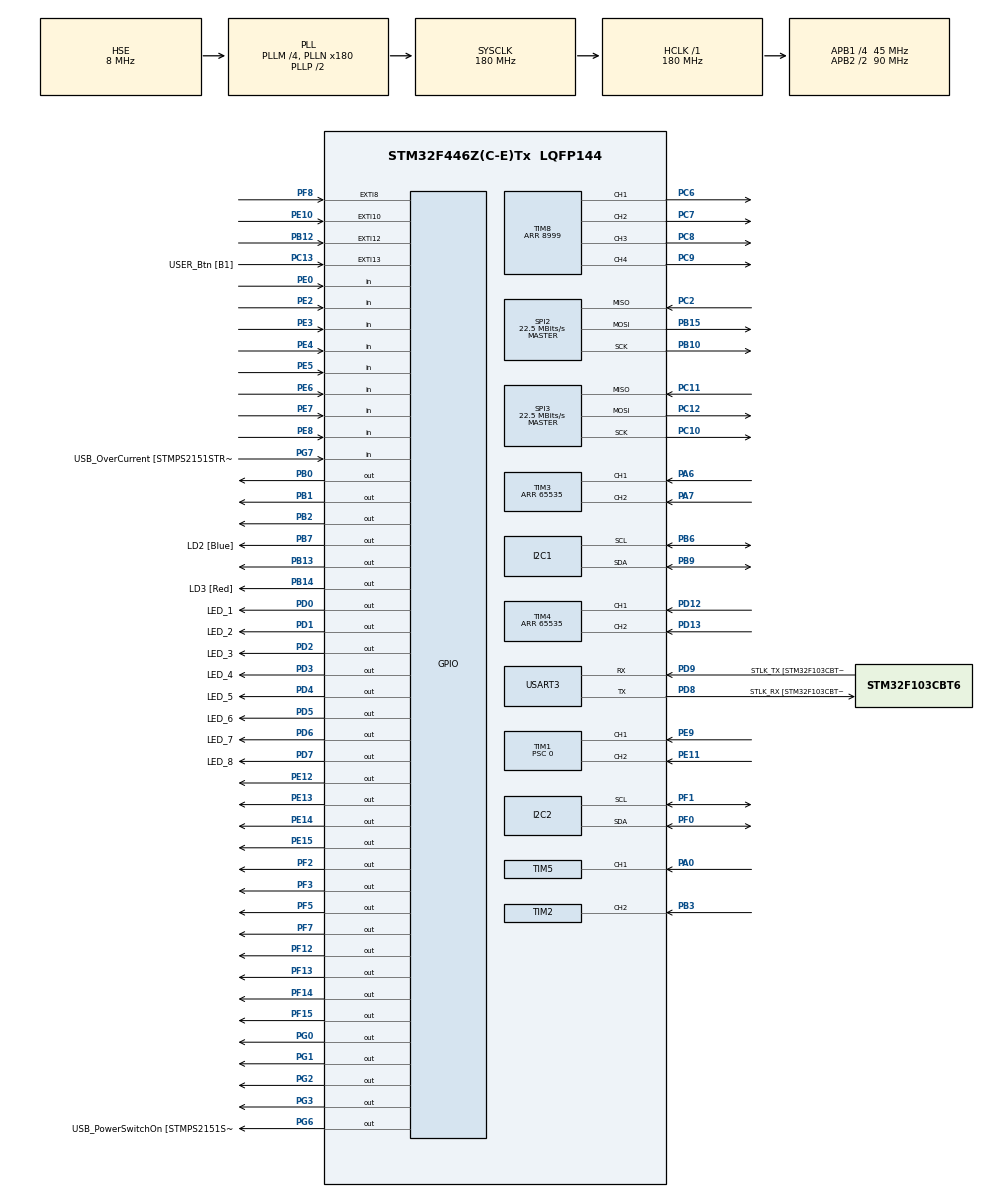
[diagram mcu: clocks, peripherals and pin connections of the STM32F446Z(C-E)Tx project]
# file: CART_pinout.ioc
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ADC1.Channel-18\#ChannelRegularConversion=ADC_CHANNEL_TEMPSENSOR
ADC1.Channel-19\#ChannelRegularConversion=ADC_CHANNEL_TEMPSENSOR
ADC1.ClockPrescaler=ADC_CLOCK_SYNC_PCLK_DIV4
ADC1.ContinuousConvMode=DISABLE
ADC1.DMAContinuousRequests=ENABLE
ADC1.DataAlign=ADC_DATAALIGN_RIGHT
ADC1.DiscontinuousConvMode=DISABLE
ADC1.EOCSelection=ADC_EOC_SEQ_CONV
ADC1.EnableAnalogWatchDog=false
ADC1.ExternalTrigConv=ADC_SOFTWARE_START
ADC1.ExternalTrigConvEdge=ADC_EXTERNALTRIGCONVEDGE_NONE
ADC1.InjNumberOfConversion=0
ADC1.NbrOfConversion=2
ADC1.NbrOfConversionFlag=1
ADC1.Rank-18\#ChannelRegularConversion=1
ADC1.Rank-19\#ChannelRegularConversion=2
ADC1.Resolution=ADC_RESOLUTION_12B
ADC1.SamplingTime-18\#ChannelRegularConversion=ADC_SAMPLETIME_3CYCLES
ADC1.SamplingTime-19\#ChannelRegularConversion=ADC_SAMPLETIME_3CYCLES
ADC1.ScanConvMode=ENABLE
ADC1.master=1
Dma.ADC1.0.Direction=DMA_PERIPH_TO_MEMORY
Dma.ADC1.0.FIFOMode=DMA_FIFOMODE_DISABLE
Dma.ADC1.0.Instance=DMA2_Stream0
Dma.ADC1.0.MemDataAlignment=DMA_MDATAALIGN_HALFWORD
Dma.ADC1.0.MemInc=DMA_MINC_ENABLE
Dma.ADC1.0.Mode=DMA_NORMAL
Dma.ADC1.0.PeriphDataAlignment=DMA_PDATAALIGN_HALFWORD
Dma.ADC1.0.PeriphInc=DMA_PINC_DISABLE
Dma.ADC1.0.Priority=DMA_PRIORITY_HIGH
Dma.Request0=ADC1
Mcu.Family=STM32F4
Mcu.Name=STM32F446Z(C-E)Tx
Mcu.Package=LQFP144
NVIC.ADC_IRQn=true\:0\:0\:false\:false\:true\:true\:true\:true
NVIC.DMA2_Stream0_IRQn=true\:0\:0\:false\:false\:true\:false\:true\:true
NVIC.EXTI15_10_IRQn=true\:0\:0\:false\:false\:true\:true\:true\:true
NVIC.EXTI9_5_IRQn=true\:0\:0\:false\:false\:true\:true\:true\:true
NVIC.PriorityGroup=NVIC_PRIORITYGROUP_4
NVIC.TIM2_IRQn=true\:0\:0\:false\:false\:true\:true\:true\:true
NVIC.TIM5_IRQn=true\:0\:0\:false\:false\:true\:true\:true\:true
NVIC.TIM6_DAC_IRQn=true\:0\:0\:false\:false\:true\:true\:true\:true
NVIC.USART3_IRQn=true\:0\:0\:false\:false\:true\:true\:true\:true
PA0-WKUP.Signal=S_TIM5_CH1
PA10.GPIO_Label=USB_ID
PA10.Signal=USB_OTG_FS_ID
PA11.GPIO_Label=USB_DM
PA11.Signal=USB_OTG_FS_DM
PA12.GPIO_Label=USB_DP
PA12.Signal=USB_OTG_FS_DP
PA13.GPIO_Label=TMS
PA13.Mode=Serial_Wire
PA13.Signal=SYS_JTMS-SWDIO
PA14.GPIO_Label=TCK
PA14.Mode=Serial_Wire
PA14.Signal=SYS_JTCK-SWCLK
PA3.Signal=ADCx_IN3
PA6.Signal=S_TIM3_CH1
PA7.Signal=S_TIM3_CH2
PA8.GPIO_Label=USB_SOF [TP1]
PA8.Signal=USB_OTG_FS_SOF
PA9.GPIO_Label=USB_VBUS
PA9.Signal=USB_OTG_FS_VBUS
PB0.Signal=GPIO_Output
PB1.Signal=GPIO_Output
PB10.Mode=Full_Duplex_Master
PB10.Signal=SPI2_SCK
PB12.Signal=GPXTI12
PB13.Signal=GPIO_Output
PB14.GPIO_Label=LD3 [Red]
PB14.Signal=GPIO_Output
PB15.Mode=Full_Duplex_Master
PB15.Signal=SPI2_MOSI
PB2.Signal=GPIO_Output
PB3.Signal=S_TIM2_CH2
PB6.GPIO_Pu=GPIO_PULLUP
PB6.Mode=I2C
PB6.Signal=I2C1_SCL
PB7.GPIO_Label=LD2 [Blue]
PB7.Signal=GPIO_Output
PB9.GPIO_Pu=GPIO_PULLUP
PB9.Mode=I2C
PB9.Signal=I2C1_SDA
PC0.Signal=ADCx_IN10
PC10.Mode=Full_Duplex_Master
PC10.Signal=SPI3_SCK
PC11.Mode=Full_Duplex_Master
PC11.Signal=SPI3_MISO
PC12.Mode=Full_Duplex_Master
PC12.Signal=SPI3_MOSI
PC13.GPIO_Label=USER_Btn [B1]
PC13.Signal=GPXTI13
PC14-OSC32_IN.Signal=RCC_OSC32_IN
PC15-OSC32_OUT.Signal=RCC_OSC32_OUT
PC2.Mode=Full_Duplex_Master
PC2.Signal=SPI2_MISO
PC3.Signal=ADCx_IN13
PC6.Signal=S_TIM8_CH1
PC7.Signal=S_TIM8_CH2
PC8.Signal=S_TIM8_CH3
PC9.Signal=S_TIM8_CH4
PD0.GPIO_Label=LED_1
PD0.Signal=GPIO_Output
PD1.GPIO_Label=LED_2
PD1.Signal=GPIO_Output
PD12.Signal=S_TIM4_CH1
PD13.Signal=S_TIM4_CH2
PD2.GPIO_Label=LED_3
PD2.Signal=GPIO_Output
PD3.GPIO_Label=LED_4
PD3.Signal=GPIO_Output
PD4.GPIO_Label=LED_5
PD4.Signal=GPIO_Output
PD5.GPIO_Label=LED_6
PD5.Signal=GPIO_Output
PD6.GPIO_Label=LED_7
PD6.Signal=GPIO_Output
PD7.GPIO_Label=LED_8
PD7.Signal=GPIO_Output
PD8.GPIO_Label=STLK_RX [STM32F103CBT6_PA3]
PD8.Mode=Asynchronous
PD8.Signal=USART3_TX
PD9.GPIO_Label=STLK_TX [STM32F103CBT6_PA2]
PD9.Mode=Asynchronous
PD9.Signal=USART3_RX
PE0.Signal=GPIO_Input
PE10.Signal=GPXTI10
PE11.Signal=S_TIM1_CH2
PE12.Signal=GPIO_Output
PE13.Signal=GPIO_Output
PE14.Signal=GPIO_Output
PE15.Signal=GPIO_Output
PE2.Signal=GPIO_Input
PE3.Signal=GPIO_Input
PE4.Signal=GPIO_Input
PE5.Signal=GPIO_Input
PE6.Signal=GPIO_Input
PE7.Signal=GPIO_Input
PE8.Signal=GPIO_Input
PE9.Signal=S_TIM1_CH1
PF0.GPIO_Pu=GPIO_PULLUP
PF0.Mode=I2C
PF0.Signal=I2C2_SDA
PF1.GPIO_Pu=GPIO_PULLUP
PF1.Mode=I2C
PF1.Signal=I2C2_SCL
PF10.Signal=ADC3_IN8
PF12.Signal=GPIO_Output
PF13.Signal=GPIO_Output
PF14.Signal=GPIO_Output
PF15.Signal=GPIO_Output
PF2.Signal=GPIO_Output
PF3.Signal=GPIO_Output
PF5.Signal=GPIO_Output
PF7.Signal=GPIO_Output
PF8.Signal=GPXTI8
PG0.Signal=GPIO_Output
PG1.Signal=GPIO_Output
PG2.Signal=GPIO_Output
PG3.Signal=GPIO_Output
PG6.GPIO_Label=USB_PowerSwitchOn [STMPS2151STR_EN]
PG6.Signal=GPIO_Output
PG7.GPIO_Label=USB_OverCurrent [STMPS2151STR_FAULT]
PG7.Signal=GPIO_Input
PH0-OSC_IN.GPIO_Label=MCO [STM32F103CBT6_PA8]
PH0-OSC_IN.Mode=HSE-External-Oscillator
PH0-OSC_IN.Signal=RCC_OSC_IN
PH1-OSC_OUT.Mode=HSE-External-Oscillator
PH1-OSC_OUT.Signal=RCC_OSC_OUT
ProjectManager.HeapSize=0x200
ProjectManager.StackSize=0x400
ProjectManager.TargetToolchain=STM32CubeIDE
RCC.48MHZClocksFreq_Value=24000000
RCC.AHBFreq_Value=180000000
RCC.APB1CLKDivider=RCC_HCLK_DIV4
RCC.APB1Freq_Value=45000000
RCC.APB1TimFreq_Value=90000000
RCC.APB2CLKDivider=RCC_HCLK_DIV2
RCC.APB2Freq_Value=90000000
RCC.APB2TimFreq_Value=180000000
RCC.CortexFreq_Value=180000000
RCC.HCLKFreq_Value=180000000
RCC.HSE_VALUE=8000000
RCC.HSI_VALUE=16000000
RCC.LSE_VALUE=32768
RCC.PLLM=4
RCC.PLLMUL=RCC_PLL_MUL9
RCC.PLLN=180
RCC.PLLSourceVirtual=RCC_PLLSOURCE_HSE
RCC.PRESCALERUSB=RCC_USBCLKSOURCE_PLL_DIV1_5
RCC.SYSCLKFreq_VALUE=180000000
RCC.SYSCLKSource=RCC_SYSCLKSOURCE_PLLCLK
RCC.SYSCLKSourceVirtual=RCC_SYSCLKSOURCE_PLLCLK
RCC.USBFreq_Value=180000000
RCC.VCOOutputFreq_Value=360000000
SH.ADCx_IN10.0=ADC1_IN10
SH.ADCx_IN10.1=ADC2_IN10
SH.ADCx_IN13.0=ADC1_IN13
SH.ADCx_IN13.1=ADC2_IN13
SH.ADCx_IN3.0=ADC1_IN3
SH.S_TIM1_CH1.0=TIM1_CH1,Encoder_Interface
SH.S_TIM1_CH2.0=TIM1_CH2,Encoder_Interface
SH.S_TIM2_CH2.0=TIM2_CH2,PWM_Input_2
SH.S_TIM3_CH1.0=TIM3_CH1,Encoder_Interface
SH.S_TIM3_CH2.0=TIM3_CH2,Encoder_Interface
SH.S_TIM4_CH1.0=TIM4_CH1,Encoder_Interface
SH.S_TIM4_CH2.0=TIM4_CH2,Encoder_Interface
SH.S_TIM5_CH1.0=TIM5_CH1,PWM_Input_1
SH.S_TIM8_CH1.0=TIM8_CH1,PWM Generation1 CH1
SH.S_TIM8_CH2.0=TIM8_CH2,PWM Generation2 CH2
SH.S_TIM8_CH3.0=TIM8_CH3,PWM Generation3 CH3
SH.S_TIM8_CH4.0=TIM8_CH4,PWM Generation4 CH4
SPI2.CalculateBaudRate=22.5 MBits/s
SPI2.Direction=SPI_DIRECTION_2LINES
SPI2.Mode=SPI_MODE_MASTER
SPI2.VirtualType=VM_MASTER
SPI3.CalculateBaudRate=22.5 MBits/s
SPI3.Direction=SPI_DIRECTION_2LINES
SPI3.Mode=SPI_MODE_MASTER
SPI3.VirtualType=VM_MASTER
TIM1.Period=65535
TIM1.Prescaler=0
TIM2.Period=4294967295
TIM3.Period=65535
TIM4.Period=65535
TIM5.Period=4294967295
TIM6.Period=17999
TIM6.Prescaler=0
TIM6.TIM_MasterOutputTrigger=TIM_TRGO_ENABLE
TIM8.Channel-PWM\ Generation1\ CH1=TIM_CHANNEL_1
TIM8.Channel-PWM\ Generation2\ CH2=TIM_CHANNEL_2
TIM8.Channel-PWM\ Generation3\ CH3=TIM_CHANNEL_3
TIM8.Channel-PWM\ Generation4\ CH4=TIM_CHANNEL_4
TIM8.ClockDivision=TIM_CLOCKDIVISION_DIV1
TIM8.OCFastMode_PWM-PWM\ Generation2\ CH2=TIM_OCFAST_ENABLE
TIM8.OCFastMode_PWM-PWM\ Generation3\ CH3=TIM_OCFAST_ENABLE
TIM8.OCFastMode_PWM-PWM\ Generation4\ CH4=TIM_OCFAST_ENABLE
TIM8.Period=8999
USART3.VirtualMode=VM_ASYNC
VP_ADC1_TempSens_Input.Mode=IN-TempSens
VP_ADC1_Vref_Input.Mode=IN-Vrefint
VP_TIM6_VS_ClockSourceINT.Mode=Enable_Timer
board=NUCLEO-F446ZE

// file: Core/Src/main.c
/* USER CODE BEGIN Header */
/**
 ******************************************************************************
 * @file           : main.c
 * @brief          : Main program body
 ******************************************************************************
 * @attention
 *
 * Copyright (c) 2025 STMicroelectronics.
 * All rights reserved.
 *
 * This software is licensed under terms that can be found in the LICENSE file
 * in the root directory of this software component.
 * If no LICENSE file comes with this software, it is provided AS-IS.
 *
 ******************************************************************************
 */
/* USER CODE END Header */
#include "main.h"

/* USER CODE BEGIN Includes */
#include <math.h>
#include <stdbool.h>

#include "stm32f4xx.h"

/* USER CODE END Includes */

/* USER CODE BEGIN PD */
#ifndef M_PI
#define M_PI 3.14159265358979323846f
#endif
/* USER CODE END PD */

ADC_HandleTypeDef hadc1;
DMA_HandleTypeDef hdma_adc1;

I2C_HandleTypeDef hi2c1;
I2C_HandleTypeDef hi2c2;

SPI_HandleTypeDef hspi2;
SPI_HandleTypeDef hspi3;

TIM_HandleTypeDef htim1;
TIM_HandleTypeDef htim2;
TIM_HandleTypeDef htim3;
TIM_HandleTypeDef htim4;
TIM_HandleTypeDef htim5;
TIM_HandleTypeDef htim6;
TIM_HandleTypeDef htim8;

UART_HandleTypeDef huart3;

/* USER CODE BEGIN PV */
bool is_stable = true;
uint32_t start_time = 0;
float prev_angle_abs = 0.0f;
float target_angle_abs = 0.0f;
float current_angle_abs = 0.0f;

// uint32_t led_timing_start = 0;
bool is_moving = false;

typedef struct {
    GPIO_TypeDef* port;
    uint16_t enable_pin;
    uint16_t direction_pin;
    uint16_t step_pin;
    uint16_t res_pin;
    TIM_HandleTypeDef* htim;
} motor_type;

motor_type MOTOR_1 = {MOTOR_1_PORT,     MOTOR_1_ENABLE_PIN, MOTOR_1_DIRECTION_PIN,
                      MOTOR_1_STEP_PIN, MOTOR_1_RES_PIN,    &htim1};
motor_type MOTOR_2 = {MOTOR_2_PORT,     MOTOR_2_ENABLE_PIN, MOTOR_2_DIRECTION_PIN,
                      MOTOR_2_STEP_PIN, MOTOR_2_RES_PIN,    &htim3};
motor_type MOTOR_3 = {MOTOR_3_PORT,     MOTOR_3_ENABLE_PIN, MOTOR_3_DIRECTION_PIN,
                      MOTOR_3_STEP_PIN, MOTOR_3_RES_PIN,    &htim4};

typedef struct {
    GPIO_TypeDef* port;
    uint16_t pin;
} led_type;
led_type LEDS[8] = {{LED_1_GPIO_Port, LED_1_Pin}, {LED_2_GPIO_Port, LED_2_Pin},
                    {LED_3_GPIO_Port, LED_3_Pin}, {LED_4_GPIO_Port, LED_4_Pin},
                    {LED_5_GPIO_Port, LED_5_Pin}, {LED_6_GPIO_Port, LED_6_Pin},
                    {LED_7_GPIO_Port, LED_7_Pin}, {LED_8_GPIO_Port, LED_8_Pin}};
/* Constants */
#define ENC_RESOLUTION 4U
#define ENC_SLOTS_PER_REV 250U
#define ENC_STEPS_PER_REV (ENC_SLOTS_PER_REV * ENC_RESOLUTION)
#define DEG_PER_STEP (360.0f / (float)ENC_STEPS_PER_REV)

#define MOT_STEPS_PER_REV 200U

#define WHEEL_DIAMETER 0.065f  // in meters
#define WHEEL_CIRCUMFERENCE (WHEEL_DIAMETER * M_PI)
#define ROBOT_WIDTH 0.297f  // in meters

// Configuration parameters
#define STABLE_THRESHOLD (5U * 1000U)  // in milliseconds
#define MOTOR_SPEED 0.5                // in revs per second

/* USER CODE END PV */

void SystemClock_Config(void);
static void MX_GPIO_Init(void);
static void MX_DMA_Init(void);
static void MX_ADC1_Init(void);
static void MX_I2C1_Init(void);
static void MX_I2C2_Init(void);
static void MX_SPI2_Init(void);
static void MX_SPI3_Init(void);
static void MX_TIM1_Init(void);
static void MX_TIM2_Init(void);
static void MX_TIM3_Init(void);
static void MX_TIM4_Init(void);
static void MX_TIM5_Init(void);
static void MX_TIM8_Init(void);
static void MX_USART3_UART_Init(void);
static void MX_TIM6_Init(void);

/* USER CODE BEGIN 0 */

static float read_current_angle(motor_type* motor) {
    int16_t enc_signed = motor->htim->Instance->CNT;
    return enc_signed * DEG_PER_STEP;
}

/**
 * Read the encoder count and convert to a 0-360 float angle.
 */
static float read_current_angle_mod_360(motor_type* motor) {
    return fmodf(read_current_angle(motor), 360.0f);
}

/**
 * Update indicator LEDs based on stable/moving state.
 */
static void update_leds(bool leds_state[8]) {
    for (int i = 0; i < 8; i++) {
        HAL_GPIO_WritePin(LEDS[i].port, LEDS[i].pin, leds_state[i] ? GPIO_PIN_SET : GPIO_PIN_RESET);
    }
}

/**
 * Reset the state machine to initial conditions.
 */
static void reset_state(uint32_t current_time) {
    is_stable = false;
    is_moving = false;
    start_time = current_time;
    target_angle_abs = 0.0f;
    current_angle_abs = 0.0f;
    prev_angle_abs = 0.0f;
    // TODO Change these vars to global
    // TODO Reset motor enable/disable pins
    HAL_GPIO_WritePin(MOTOR_1.port, MOTOR_1.enable_pin, MOTOR_ENABLE);
    HAL_GPIO_WritePin(MOTOR_2.port, MOTOR_2.enable_pin, MOTOR_ENABLE);
    HAL_GPIO_WritePin(MOTOR_3.port, MOTOR_3.enable_pin, MOTOR_DISABLE);
}

/**
 * Handle external reset button (PE8) which forces state reset.
 */
static void handle_reset_button(uint32_t current_time, bool* stable, bool* moving,
                                uint32_t* start_time_ptr) {
    if (HAL_GPIO_ReadPin(GPIOE, GPIO_PIN_8) == GPIO_PIN_SET) {
        reset_state(current_time);
    }
}

/**
 * Process stability detection when not currently moving.
 * If the angle changes, restart the stability timer. If unchanged for
 * STABLE_THRESHOLD, mark target and start moving.
 */
static void process_stability(uint32_t current_time) {
    if (prev_angle_abs != current_angle_abs) {
        /* Angle changed while stationary — start/restart stability timer */
        is_stable = false;
        start_time = current_time;
        is_moving = false;
    } else {
        /* Angle unchanged — check stability timeout */
        is_stable = true;
        if ((current_time - start_time) > STABLE_THRESHOLD) {
            target_angle_abs = current_angle_abs;
            is_moving = true;
        }
    }
}

static void turn_motor(motor_type* motor, float angle_to_rotate, uint8_t direction, float speed) {
    angle_to_rotate = fabs(angle_to_rotate);

    HAL_GPIO_WritePin(motor->port, motor->enable_pin, MOTOR_ENABLE);
    HAL_GPIO_WritePin(motor->port, motor->direction_pin, direction);
    HAL_GPIO_WritePin(motor->port, motor->res_pin, GPIO_PIN_RESET);

    float motor_start_angle = read_current_angle(motor);

    uint32_t speed_steps_per_s = speed * MOT_STEPS_PER_REV;
    uint32_t delay_ms = 1000 / speed_steps_per_s;
    uint32_t delay_ms_half = delay_ms / 2;

    static uint32_t last_print_time = 0;

    while (fabs(read_current_angle(motor) - motor_start_angle) <= angle_to_rotate) {
        // UART debug: print fabs(current_angle - motor_start_angle) and angle_to_rotate
        uint32_t current_time = HAL_GetTick();
        bool should_tick = current_time % 500 < 250;
        bool leds_to_tick[8];
        if (direction == 1) {
            memcpy(leds_to_tick, (bool[8]){1, 1, 1, 1, 0, 0, 0, 0}, sizeof(leds_to_tick));
        } else {
            memcpy(leds_to_tick, (bool[8]){0, 0, 0, 0, 1, 1, 1, 1}, sizeof(leds_to_tick));
        }
    if (should_tick) {
        update_leds((bool[8]){0, 0, 0, 0, 0, 0, 0, 0});
        } else {
            update_leds(leds_to_tick);
        }

        current_time = HAL_GetTick();
        if (current_time - last_print_time >= 900) {
            last_print_time = current_time;
            char debug_buf[128];

            float angle_diff_deg = target_angle_abs;
            if (angle_diff_deg > 180.0f) {
                angle_diff_deg -= 360.0f;
            } else if (angle_diff_deg < -180.0f) {
                angle_diff_deg += 360.0f;
            }

            float rotation_progress_frac = fabs(read_current_angle(motor) - motor_start_angle) / angle_to_rotate;
            int32_t angle_int = (int32_t)(target_angle_abs * 10000);
            int32_t diff_int = angle_int * rotation_progress_frac;

            sprintf(debug_buf, "fabs(cur_angle - start): %ld.%04ld, angle_to_rotate: %ld.%04ld\r\n",
                    (long)(diff_int / 10000), (long)(abs(diff_int) % 10000),
                    (long)(angle_int / 10000), (long)(abs(angle_int) % 10000));
            HAL_UART_Transmit(&huart3, (uint8_t*)debug_buf, strlen(debug_buf), HAL_MAX_DELAY);

            sprintf(debug_buf, "Enc1: %lu, Enc2: %lu, Diff: %ld\r\n",
                (unsigned long)MOTOR_1.htim->Instance->CNT,
                (unsigned long)MOTOR_2.htim->Instance->CNT,
                (long)(MOTOR_1.htim->Instance->CNT - MOTOR_2.htim->Instance->CNT));
            HAL_UART_Transmit(&huart3, (uint8_t*)debug_buf, strlen(debug_buf), HAL_MAX_DELAY);
        }

        HAL_GPIO_WritePin(motor->port, motor->step_pin, GPIO_PIN_SET);
        HAL_Delay(delay_ms_half);
        HAL_GPIO_WritePin(motor->port, motor->step_pin, GPIO_PIN_RESET);
        HAL_Delay(delay_ms_half);
    }
    HAL_GPIO_WritePin(motor->port, motor->enable_pin, MOTOR_DISABLE);
}

static void reset_robot_arm(float speed) {
    int16_t enc_signed = MOTOR_3.htim->Instance->CNT;
    // char debug_buf[64];
    // sprintf(debug_buf, "CNT: %d\r\n", enc_signed);
    // HAL_UART_Transmit(&huart3, (uint8_t*)debug_buf, strlen(debug_buf), HAL_MAX_DELAY);

    HAL_GPIO_WritePin(MOTOR_3.port, MOTOR_3.enable_pin, MOTOR_ENABLE);
    HAL_GPIO_WritePin(MOTOR_3.port, MOTOR_3.res_pin, GPIO_PIN_RESET);

    if (enc_signed > 0) {
        HAL_GPIO_WritePin(MOTOR_3.port, MOTOR_3.direction_pin, 1);
    } else {
        HAL_GPIO_WritePin(MOTOR_3.port, MOTOR_3.direction_pin, 0);
    }

    uint32_t speed_steps_per_s = speed * MOT_STEPS_PER_REV;
    uint32_t delay_ms = 1000 / speed_steps_per_s;
    uint32_t delay_ms_half = delay_ms / 2;

    while (enc_signed > 2 || enc_signed < -2) {
        HAL_GPIO_WritePin(MOTOR_3.port, MOTOR_3.step_pin, GPIO_PIN_SET);
        HAL_Delay(delay_ms_half);
        HAL_GPIO_WritePin(MOTOR_3.port, MOTOR_3.step_pin, GPIO_PIN_RESET);
        HAL_Delay(delay_ms_half);
        enc_signed = MOTOR_3.htim->Instance->CNT;
        // sprintf(debug_buf, "CNT: %d\r\n", enc_signed);
        // HAL_UART_Transmit(&huart3, (uint8_t*)debug_buf, strlen(debug_buf), HAL_MAX_DELAY);
    }
    HAL_GPIO_WritePin(MOTOR_3.port, MOTOR_3.enable_pin, MOTOR_DISABLE);
}

// static void turn_motor_with_led(motor_type* motor, float angle_to_rotate, float direction,
//                                 float speed, GPIO_TypeDef* led_port, uint16_t led_pin) {
//     HAL_GPIO_WritePin(led_port, led_pin, GPIO_PIN_SET);
//     turn_motor(motor, angle_to_rotate, direction, speed);
//     HAL_GPIO_WritePin(led_port, led_pin, GPIO_PIN_RESET);
// }

static void rotate_robot_to_angle(float current_angle_abs, float target_angle_abs) {
    // Placeholder for motor control logic to rotate robot to target_angle_abs
    // This would involve calculating the required motor steps and
    // commanding the motor drivers accordingly.

    float angle_diff_deg = target_angle_abs;
    if (angle_diff_deg > 180.0f) {
        angle_diff_deg -= 360.0f;
    } else if (angle_diff_deg < -180.0f) {
        angle_diff_deg += 360.0f;
    }
    float angle_diff_rad = angle_diff_deg * M_PI / 180.0f;
    float num_of_revs = ROBOT_WIDTH * angle_diff_rad / WHEEL_CIRCUMFERENCE;
    float angle_to_rotate = num_of_revs * 360.0f;

    float robot_turn_direction = (angle_to_rotate > 0) ? 1 : -1;

    // TODO Deal with the case where the number of revolutions is less than 0.1

    if (robot_turn_direction == 1) {
        turn_motor(&MOTOR_1, angle_to_rotate, 1, MOTOR_SPEED);
    } else {
        turn_motor(&MOTOR_2, angle_to_rotate, 0, MOTOR_SPEED);
    }

    reset_robot_arm(MOTOR_SPEED);
    reset_state(HAL_GetTick());
}

/* USER CODE END 0 */

int main(void) {

    /* MCU Configuration--------------------------------------------------------*/

    /* Reset of all peripherals, Initializes the Flash interface and the Systick.
     */
    HAL_Init();

    /* Configure the system clock */
    SystemClock_Config();

    /* Initialize all configured peripherals */
    MX_GPIO_Init();
    MX_DMA_Init();
    MX_ADC1_Init();
    MX_I2C1_Init();
    MX_I2C2_Init();
    MX_SPI2_Init();
    MX_SPI3_Init();
    MX_TIM1_Init();
    MX_TIM2_Init();
    MX_TIM3_Init();
    MX_TIM4_Init();
    MX_TIM5_Init();
    MX_TIM8_Init();
    MX_USART3_UART_Init();
    MX_TIM6_Init();
    /* USER CODE BEGIN 2 */

    HAL_TIM_Encoder_Start(&htim4, TIM_CHANNEL_ALL);
    HAL_TIM_Encoder_Start(&htim1, TIM_CHANNEL_ALL);
    HAL_TIM_Encoder_Start(&htim3, TIM_CHANNEL_ALL);
    uint32_t current_time = HAL_GetTick();
    reset_state(current_time);

    // turn_motor_with_led(&MOTOR_1, 1000, 1, MOTOR_SPEED, LED_8_GPIO_Port, LED_8_Pin);
    // turn_motor_with_led(&MOTOR_2, 1000, 1, MOTOR_SPEED, LED_7_GPIO_Port, LED_7_Pin);
    /* USER CODE END 2 */

    /* Infinite loop */
    /* USER CODE BEGIN WHILE */
    while (1) {
        /* Read angle and time */
        current_angle_abs = read_current_angle(&MOTOR_3);
        current_time = HAL_GetTick();
        bool should_tick = current_time % 500 < 250;

        /* External reset button handling */
        handle_reset_button(current_time, &is_stable, &is_moving, &start_time);

        if (!is_moving) {
            /* Not moving: check stability and possibly start move */
            process_stability(current_time);
            if (should_tick % 500 < 250) {
                update_leds(should_tick ? (bool[8]){1, 1, 1, 1, 1, 1, 1, 1} : (bool[8]){0, 0, 0, 0, 0, 0, 0, 0});
            }
        } else {
            /* Currently moving — keep state */
            is_stable = false;
            // Rotate robot towards target angle
            rotate_robot_to_angle(current_angle_abs, target_angle_abs);
        }

        prev_angle_abs = current_angle_abs;
        /* USER CODE END WHILE */

    }
}

void SystemClock_Config(void) {
    RCC_OscInitTypeDef RCC_OscInitStruct = {0};
    RCC_ClkInitTypeDef RCC_ClkInitStruct = {0};

    /** Configure the main internal regulator output voltage
     */
    __HAL_RCC_PWR_CLK_ENABLE();
    __HAL_PWR_VOLTAGESCALING_CONFIG(PWR_REGULATOR_VOLTAGE_SCALE1);

    /** Initializes the RCC Oscillators according to the specified parameters
     * in the RCC_OscInitTypeDef structure.
     */
    RCC_OscInitStruct.OscillatorType = RCC_OSCILLATORTYPE_HSE;
    RCC_OscInitStruct.HSEState = RCC_HSE_ON;
    RCC_OscInitStruct.PLL.PLLState = RCC_PLL_ON;
    RCC_OscInitStruct.PLL.PLLSource = RCC_PLLSOURCE_HSE;
    RCC_OscInitStruct.PLL.PLLM = 4;
    RCC_OscInitStruct.PLL.PLLN = 180;
    RCC_OscInitStruct.PLL.PLLP = RCC_PLLP_DIV2;
    RCC_OscInitStruct.PLL.PLLQ = 2;
    RCC_OscInitStruct.PLL.PLLR = 2;
    if (HAL_RCC_OscConfig(&RCC_OscInitStruct) != HAL_OK) {
        Error_Handler();
    }

    /** Activate the Over-Drive mode
     */
    if (HAL_PWREx_EnableOverDrive() != HAL_OK) {
        Error_Handler();
    }

    /** Initializes the CPU, AHB and APB buses clocks
     */
    RCC_ClkInitStruct.ClockType =
        RCC_CLOCKTYPE_HCLK | RCC_CLOCKTYPE_SYSCLK | RCC_CLOCKTYPE_PCLK1 | RCC_CLOCKTYPE_PCLK2;
    RCC_ClkInitStruct.SYSCLKSource = RCC_SYSCLKSOURCE_PLLCLK;
    RCC_ClkInitStruct.AHBCLKDivider = RCC_SYSCLK_DIV1;
    RCC_ClkInitStruct.APB1CLKDivider = RCC_HCLK_DIV4;
    RCC_ClkInitStruct.APB2CLKDivider = RCC_HCLK_DIV2;

    if (HAL_RCC_ClockConfig(&RCC_ClkInitStruct, FLASH_LATENCY_5) != HAL_OK) {
        Error_Handler();
    }
}

static void MX_ADC1_Init(void) {

    ADC_ChannelConfTypeDef sConfig = {0};

    /** Configure the global features of the ADC (Clock, Resolution, Data
     * Alignment and number of conversion)
     */
    hadc1.Instance = ADC1;
    hadc1.Init.ClockPrescaler = ADC_CLOCK_SYNC_PCLK_DIV4;
    hadc1.Init.Resolution = ADC_RESOLUTION_12B;
    hadc1.Init.ScanConvMode = ENABLE;
    hadc1.Init.ContinuousConvMode = DISABLE;
    hadc1.Init.DiscontinuousConvMode = DISABLE;
    hadc1.Init.ExternalTrigConvEdge = ADC_EXTERNALTRIGCONVEDGE_NONE;
    hadc1.Init.ExternalTrigConv = ADC_SOFTWARE_START;
    hadc1.Init.DataAlign = ADC_DATAALIGN_RIGHT;
    hadc1.Init.NbrOfConversion = 2;
    hadc1.Init.DMAContinuousRequests = ENABLE;
    hadc1.Init.EOCSelection = ADC_EOC_SEQ_CONV;
    if (HAL_ADC_Init(&hadc1) != HAL_OK) {
        Error_Handler();
    }

    /** Configure for the selected ADC regular channel its corresponding rank in
     * the sequencer and its sample time.
     */
    sConfig.Channel = ADC_CHANNEL_TEMPSENSOR;
    sConfig.Rank = 1;
    sConfig.SamplingTime = ADC_SAMPLETIME_3CYCLES;
    if (HAL_ADC_ConfigChannel(&hadc1, &sConfig) != HAL_OK) {
        Error_Handler();
    }

    /** Configure for the selected ADC regular channel its corresponding rank in
     * the sequencer and its sample time.
     */
    sConfig.Rank = 2;
    if (HAL_ADC_ConfigChannel(&hadc1, &sConfig) != HAL_OK) {
        Error_Handler();
    }
}

static void MX_I2C1_Init(void) {

    hi2c1.Instance = I2C1;
    hi2c1.Init.ClockSpeed = 100000;
    hi2c1.Init.DutyCycle = I2C_DUTYCYCLE_2;
    hi2c1.Init.OwnAddress1 = 0;
    hi2c1.Init.AddressingMode = I2C_ADDRESSINGMODE_7BIT;
    hi2c1.Init.DualAddressMode = I2C_DUALADDRESS_DISABLE;
    hi2c1.Init.OwnAddress2 = 0;
    hi2c1.Init.GeneralCallMode = I2C_GENERALCALL_DISABLE;
    hi2c1.Init.NoStretchMode = I2C_NOSTRETCH_DISABLE;
    if (HAL_I2C_Init(&hi2c1) != HAL_OK) {
        Error_Handler();
    }
}

static void MX_I2C2_Init(void) {

    hi2c2.Instance = I2C2;
    hi2c2.Init.ClockSpeed = 100000;
    hi2c2.Init.DutyCycle = I2C_DUTYCYCLE_2;
    hi2c2.Init.OwnAddress1 = 0;
    hi2c2.Init.AddressingMode = I2C_ADDRESSINGMODE_7BIT;
    hi2c2.Init.DualAddressMode = I2C_DUALADDRESS_DISABLE;
    hi2c2.Init.OwnAddress2 = 0;
    hi2c2.Init.GeneralCallMode = I2C_GENERALCALL_DISABLE;
    hi2c2.Init.NoStretchMode = I2C_NOSTRETCH_DISABLE;
    if (HAL_I2C_Init(&hi2c2) != HAL_OK) {
        Error_Handler();
    }
}

static void MX_SPI2_Init(void) {

    /* SPI2 parameter configuration*/
    hspi2.Instance = SPI2;
    hspi2.Init.Mode = SPI_MODE_MASTER;
    hspi2.Init.Direction = SPI_DIRECTION_2LINES;
    hspi2.Init.DataSize = SPI_DATASIZE_8BIT;
    hspi2.Init.CLKPolarity = SPI_POLARITY_LOW;
    hspi2.Init.CLKPhase = SPI_PHASE_1EDGE;
    hspi2.Init.NSS = SPI_NSS_SOFT;
    hspi2.Init.BaudRatePrescaler = SPI_BAUDRATEPRESCALER_2;
    hspi2.Init.FirstBit = SPI_FIRSTBIT_MSB;
    hspi2.Init.TIMode = SPI_TIMODE_DISABLE;
    hspi2.Init.CRCCalculation = SPI_CRCCALCULATION_DISABLE;
    hspi2.Init.CRCPolynomial = 10;
    if (HAL_SPI_Init(&hspi2) != HAL_OK) {
        Error_Handler();
    }
}

static void MX_SPI3_Init(void) {

    /* SPI3 parameter configuration*/
    hspi3.Instance = SPI3;
    hspi3.Init.Mode = SPI_MODE_MASTER;
    hspi3.Init.Direction = SPI_DIRECTION_2LINES;
    hspi3.Init.DataSize = SPI_DATASIZE_8BIT;
    hspi3.Init.CLKPolarity = SPI_POLARITY_LOW;
    hspi3.Init.CLKPhase = SPI_PHASE_1EDGE;
    hspi3.Init.NSS = SPI_NSS_SOFT;
    hspi3.Init.BaudRatePrescaler = SPI_BAUDRATEPRESCALER_2;
    hspi3.Init.FirstBit = SPI_FIRSTBIT_MSB;
    hspi3.Init.TIMode = SPI_TIMODE_DISABLE;
    hspi3.Init.CRCCalculation = SPI_CRCCALCULATION_DISABLE;
    hspi3.Init.CRCPolynomial = 10;
    if (HAL_SPI_Init(&hspi3) != HAL_OK) {
        Error_Handler();
    }
}

static void MX_TIM1_Init(void) {

    TIM_Encoder_InitTypeDef sConfig = {0};
    TIM_MasterConfigTypeDef sMasterConfig = {0};

    htim1.Instance = TIM1;
    htim1.Init.Prescaler = 0;
    htim1.Init.CounterMode = TIM_COUNTERMODE_UP;
    htim1.Init.Period = 65535;
    htim1.Init.ClockDivision = TIM_CLOCKDIVISION_DIV1;
    htim1.Init.RepetitionCounter = 0;
    htim1.Init.AutoReloadPreload = TIM_AUTORELOAD_PRELOAD_DISABLE;
    sConfig.EncoderMode = TIM_ENCODERMODE_TI1;
    sConfig.IC1Polarity = TIM_ICPOLARITY_RISING;
    sConfig.IC1Selection = TIM_ICSELECTION_DIRECTTI;
    sConfig.IC1Prescaler = TIM_ICPSC_DIV1;
    sConfig.IC1Filter = 0;
    sConfig.IC2Polarity = TIM_ICPOLARITY_RISING;
    sConfig.IC2Selection = TIM_ICSELECTION_DIRECTTI;
    sConfig.IC2Prescaler = TIM_ICPSC_DIV1;
    sConfig.IC2Filter = 0;
    if (HAL_TIM_Encoder_Init(&htim1, &sConfig) != HAL_OK) {
        Error_Handler();
    }
    sMasterConfig.MasterOutputTrigger = TIM_TRGO_RESET;
    sMasterConfig.MasterSlaveMode = TIM_MASTERSLAVEMODE_DISABLE;
    if (HAL_TIMEx_MasterConfigSynchronization(&htim1, &sMasterConfig) != HAL_OK) {
        Error_Handler();
    }
}

static void MX_TIM2_Init(void) {

    TIM_SlaveConfigTypeDef sSlaveConfig = {0};
    TIM_IC_InitTypeDef sConfigIC = {0};
    TIM_MasterConfigTypeDef sMasterConfig = {0};

    htim2.Instance = TIM2;
    htim2.Init.Prescaler = 0;
    htim2.Init.CounterMode = TIM_COUNTERMODE_UP;
    htim2.Init.Period = 4294967295;
    htim2.Init.ClockDivision = TIM_CLOCKDIVISION_DIV1;
    htim2.Init.AutoReloadPreload = TIM_AUTORELOAD_PRELOAD_DISABLE;
    if (HAL_TIM_IC_Init(&htim2) != HAL_OK) {
        Error_Handler();
    }
    sSlaveConfig.SlaveMode = TIM_SLAVEMODE_RESET;
    sSlaveConfig.InputTrigger = TIM_TS_TI2FP2;
    sSlaveConfig.TriggerPolarity = TIM_INPUTCHANNELPOLARITY_FALLING;
    sSlaveConfig.TriggerPrescaler = TIM_ICPSC_DIV1;
    sSlaveConfig.TriggerFilter = 0;
    if (HAL_TIM_SlaveConfigSynchro(&htim2, &sSlaveConfig) != HAL_OK) {
        Error_Handler();
    }
    sConfigIC.ICPolarity = TIM_INPUTCHANNELPOLARITY_RISING;
    sConfigIC.ICSelection = TIM_ICSELECTION_INDIRECTTI;
    sConfigIC.ICPrescaler = TIM_ICPSC_DIV1;
    sConfigIC.ICFilter = 0;
    if (HAL_TIM_IC_ConfigChannel(&htim2, &sConfigIC, TIM_CHANNEL_1) != HAL_OK) {
        Error_Handler();
    }
    sConfigIC.ICPolarity = TIM_INPUTCHANNELPOLARITY_FALLING;
    sConfigIC.ICSelection = TIM_ICSELECTION_DIRECTTI;
    if (HAL_TIM_IC_ConfigChannel(&htim2, &sConfigIC, TIM_CHANNEL_2) != HAL_OK) {
        Error_Handler();
    }
    sMasterConfig.MasterOutputTrigger = TIM_TRGO_RESET;
    sMasterConfig.MasterSlaveMode = TIM_MASTERSLAVEMODE_DISABLE;
    if (HAL_TIMEx_MasterConfigSynchronization(&htim2, &sMasterConfig) != HAL_OK) {
        Error_Handler();
    }
}

static void MX_TIM3_Init(void) {

    TIM_Encoder_InitTypeDef sConfig = {0};
    TIM_MasterConfigTypeDef sMasterConfig = {0};

    htim3.Instance = TIM3;
    htim3.Init.Prescaler = 0;
    htim3.Init.CounterMode = TIM_COUNTERMODE_UP;
    htim3.Init.Period = 65535;
    htim3.Init.ClockDivision = TIM_CLOCKDIVISION_DIV1;
    htim3.Init.AutoReloadPreload = TIM_AUTORELOAD_PRELOAD_DISABLE;
    sConfig.EncoderMode = TIM_ENCODERMODE_TI1;
    sConfig.IC1Polarity = TIM_ICPOLARITY_RISING;
    sConfig.IC1Selection = TIM_ICSELECTION_DIRECTTI;
    sConfig.IC1Prescaler = TIM_ICPSC_DIV1;
    sConfig.IC1Filter = 0;
    sConfig.IC2Polarity = TIM_ICPOLARITY_RISING;
    sConfig.IC2Selection = TIM_ICSELECTION_DIRECTTI;
    sConfig.IC2Prescaler = TIM_ICPSC_DIV1;
    sConfig.IC2Filter = 0;
    if (HAL_TIM_Encoder_Init(&htim3, &sConfig) != HAL_OK) {
        Error_Handler();
    }
    sMasterConfig.MasterOutputTrigger = TIM_TRGO_RESET;
    sMasterConfig.MasterSlaveMode = TIM_MASTERSLAVEMODE_DISABLE;
    if (HAL_TIMEx_MasterConfigSynchronization(&htim3, &sMasterConfig) != HAL_OK) {
        Error_Handler();
    }
}

static void MX_TIM4_Init(void) {

    TIM_Encoder_InitTypeDef sConfig = {0};
    TIM_MasterConfigTypeDef sMasterConfig = {0};

    htim4.Instance = TIM4;
    htim4.Init.Prescaler = 0;
    htim4.Init.CounterMode = TIM_COUNTERMODE_UP;
    htim4.Init.Period = 65535;
    htim4.Init.ClockDivision = TIM_CLOCKDIVISION_DIV1;
    htim4.Init.AutoReloadPreload = TIM_AUTORELOAD_PRELOAD_DISABLE;
    sConfig.EncoderMode = TIM_ENCODERMODE_TI1;
    sConfig.IC1Polarity = TIM_ICPOLARITY_RISING;
    sConfig.IC1Selection = TIM_ICSELECTION_DIRECTTI;
    sConfig.IC1Prescaler = TIM_ICPSC_DIV1;
    sConfig.IC1Filter = 0;
    sConfig.IC2Polarity = TIM_ICPOLARITY_RISING;
    sConfig.IC2Selection = TIM_ICSELECTION_DIRECTTI;
    sConfig.IC2Prescaler = TIM_ICPSC_DIV1;
    sConfig.IC2Filter = 0;
    if (HAL_TIM_Encoder_Init(&htim4, &sConfig) != HAL_OK) {
        Error_Handler();
    }
    sMasterConfig.MasterOutputTrigger = TIM_TRGO_RESET;
    sMasterConfig.MasterSlaveMode = TIM_MASTERSLAVEMODE_DISABLE;
    if (HAL_TIMEx_MasterConfigSynchronization(&htim4, &sMasterConfig) != HAL_OK) {
        Error_Handler();
    }
}

static void MX_TIM5_Init(void) {

    TIM_SlaveConfigTypeDef sSlaveConfig = {0};
    TIM_IC_InitTypeDef sConfigIC = {0};
    TIM_MasterConfigTypeDef sMasterConfig = {0};

    htim5.Instance = TIM5;
    htim5.Init.Prescaler = 0;
    htim5.Init.CounterMode = TIM_COUNTERMODE_UP;
    htim5.Init.Period = 4294967295;
    htim5.Init.ClockDivision = TIM_CLOCKDIVISION_DIV1;
    htim5.Init.AutoReloadPreload = TIM_AUTORELOAD_PRELOAD_DISABLE;
    if (HAL_TIM_IC_Init(&htim5) != HAL_OK) {
        Error_Handler();
    }
    sSlaveConfig.SlaveMode = TIM_SLAVEMODE_RESET;
    sSlaveConfig.InputTrigger = TIM_TS_TI1FP1;
    sSlaveConfig.TriggerPolarity = TIM_INPUTCHANNELPOLARITY_RISING;
    sSlaveConfig.TriggerPrescaler = TIM_ICPSC_DIV1;
    sSlaveConfig.TriggerFilter = 0;
    if (HAL_TIM_SlaveConfigSynchro(&htim5, &sSlaveConfig) != HAL_OK) {
        Error_Handler();
    }
    sConfigIC.ICPolarity = TIM_INPUTCHANNELPOLARITY_RISING;
    sConfigIC.ICSelection = TIM_ICSELECTION_DIRECTTI;
    sConfigIC.ICPrescaler = TIM_ICPSC_DIV1;
    sConfigIC.ICFilter = 0;
    if (HAL_TIM_IC_ConfigChannel(&htim5, &sConfigIC, TIM_CHANNEL_1) != HAL_OK) {
        Error_Handler();
    }
    sConfigIC.ICPolarity = TIM_INPUTCHANNELPOLARITY_FALLING;
    sConfigIC.ICSelection = TIM_ICSELECTION_INDIRECTTI;
    if (HAL_TIM_IC_ConfigChannel(&htim5, &sConfigIC, TIM_CHANNEL_2) != HAL_OK) {
        Error_Handler();
    }
    sMasterConfig.MasterOutputTrigger = TIM_TRGO_RESET;
    sMasterConfig.MasterSlaveMode = TIM_MASTERSLAVEMODE_DISABLE;
    if (HAL_TIMEx_MasterConfigSynchronization(&htim5, &sMasterConfig) != HAL_OK) {
        Error_Handler();
    }
}

static void MX_TIM6_Init(void) {

    TIM_MasterConfigTypeDef sMasterConfig = {0};

    htim6.Instance = TIM6;
    htim6.Init.Prescaler = 0;
    htim6.Init.CounterMode = TIM_COUNTERMODE_UP;
    htim6.Init.Period = 17999;
    htim6.Init.AutoReloadPreload = TIM_AUTORELOAD_PRELOAD_DISABLE;
    if (HAL_TIM_Base_Init(&htim6) != HAL_OK) {
        Error_Handler();
    }
    sMasterConfig.MasterOutputTrigger = TIM_TRGO_ENABLE;
    sMasterConfig.MasterSlaveMode = TIM_MASTERSLAVEMODE_DISABLE;
    if (HAL_TIMEx_MasterConfigSynchronization(&htim6, &sMasterConfig) != HAL_OK) {
        Error_Handler();
    }
}

static void MX_TIM8_Init(void) {

    TIM_MasterConfigTypeDef sMasterConfig = {0};
    TIM_OC_InitTypeDef sConfigOC = {0};
    TIM_BreakDeadTimeConfigTypeDef sBreakDeadTimeConfig = {0};

    htim8.Instance = TIM8;
    htim8.Init.Prescaler = 0;
    htim8.Init.CounterMode = TIM_COUNTERMODE_UP;
    htim8.Init.Period = 8999;
    htim8.Init.ClockDivision = TIM_CLOCKDIVISION_DIV1;
    htim8.Init.RepetitionCounter = 0;
    htim8.Init.AutoReloadPreload = TIM_AUTORELOAD_PRELOAD_DISABLE;
    if (HAL_TIM_PWM_Init(&htim8) != HAL_OK) {
        Error_Handler();
    }
    sMasterConfig.MasterOutputTrigger = TIM_TRGO_RESET;
    sMasterConfig.MasterSlaveMode = TIM_MASTERSLAVEMODE_DISABLE;
    if (HAL_TIMEx_MasterConfigSynchronization(&htim8, &sMasterConfig) != HAL_OK) {
        Error_Handler();
    }
    sConfigOC.OCMode = TIM_OCMODE_PWM1;
    sConfigOC.Pulse = 0;
    sConfigOC.OCPolarity = TIM_OCPOLARITY_HIGH;
    sConfigOC.OCNPolarity = TIM_OCNPOLARITY_HIGH;
    sConfigOC.OCFastMode = TIM_OCFAST_DISABLE;
    sConfigOC.OCIdleState = TIM_OCIDLESTATE_RESET;
    sConfigOC.OCNIdleState = TIM_OCNIDLESTATE_RESET;
    if (HAL_TIM_PWM_ConfigChannel(&htim8, &sConfigOC, TIM_CHANNEL_1) != HAL_OK) {
        Error_Handler();
    }
    sConfigOC.OCFastMode = TIM_OCFAST_ENABLE;
    if (HAL_TIM_PWM_ConfigChannel(&htim8, &sConfigOC, TIM_CHANNEL_2) != HAL_OK) {
        Error_Handler();
    }
    if (HAL_TIM_PWM_ConfigChannel(&htim8, &sConfigOC, TIM_CHANNEL_3) != HAL_OK) {
        Error_Handler();
    }
    if (HAL_TIM_PWM_ConfigChannel(&htim8, &sConfigOC, TIM_CHANNEL_4) != HAL_OK) {
        Error_Handler();
    }
    sBreakDeadTimeConfig.OffStateRunMode = TIM_OSSR_DISABLE;
    sBreakDeadTimeConfig.OffStateIDLEMode = TIM_OSSI_DISABLE;
    sBreakDeadTimeConfig.LockLevel = TIM_LOCKLEVEL_OFF;
    sBreakDeadTimeConfig.DeadTime = 0;
    sBreakDeadTimeConfig.BreakState = TIM_BREAK_DISABLE;
    sBreakDeadTimeConfig.BreakPolarity = TIM_BREAKPOLARITY_HIGH;
    sBreakDeadTimeConfig.AutomaticOutput = TIM_AUTOMATICOUTPUT_DISABLE;
    if (HAL_TIMEx_ConfigBreakDeadTime(&htim8, &sBreakDeadTimeConfig) != HAL_OK) {
        Error_Handler();
    }
    HAL_TIM_MspPostInit(&htim8);
}

static void MX_USART3_UART_Init(void) {

    huart3.Instance = USART3;
    huart3.Init.BaudRate = 115200;
    huart3.Init.WordLength = UART_WORDLENGTH_8B;
    huart3.Init.StopBits = UART_STOPBITS_1;
    huart3.Init.Parity = UART_PARITY_NONE;
    huart3.Init.Mode = UART_MODE_TX_RX;
    huart3.Init.HwFlowCtl = UART_HWCONTROL_NONE;
    huart3.Init.OverSampling = UART_OVERSAMPLING_16;
    if (HAL_UART_Init(&huart3) != HAL_OK) {
        Error_Handler();
    }
}

static void MX_DMA_Init(void) {
    /* DMA controller clock enable */
    __HAL_RCC_DMA2_CLK_ENABLE();

    /* DMA interrupt init */
    /* DMA2_Stream0_IRQn interrupt configuration */
    HAL_NVIC_SetPriority(DMA2_Stream0_IRQn, 0, 0);
    HAL_NVIC_EnableIRQ(DMA2_Stream0_IRQn);
}

static void MX_GPIO_Init(void) {
    GPIO_InitTypeDef GPIO_InitStruct = {0};

    /* GPIO Ports Clock Enable */
    __HAL_RCC_GPIOE_CLK_ENABLE();
    __HAL_RCC_GPIOC_CLK_ENABLE();
    __HAL_RCC_GPIOF_CLK_ENABLE();
    __HAL_RCC_GPIOH_CLK_ENABLE();
    __HAL_RCC_GPIOA_CLK_ENABLE();
    __HAL_RCC_GPIOB_CLK_ENABLE();
    __HAL_RCC_GPIOG_CLK_ENABLE();
    __HAL_RCC_GPIOD_CLK_ENABLE();

    /*Configure GPIO pin Output Level */
    HAL_GPIO_WritePin(GPIOF,
                      GPIO_PIN_2 | GPIO_PIN_3 | GPIO_PIN_5 | GPIO_PIN_7 | GPIO_PIN_12 |
                          GPIO_PIN_13 | GPIO_PIN_14 | GPIO_PIN_15,
                      GPIO_PIN_RESET);

    /*Configure GPIO pin Output Level */
    HAL_GPIO_WritePin(GPIOB, GPIO_PIN_0 | GPIO_PIN_1 | GPIO_PIN_2 | GPIO_PIN_13 | LD3_Pin | LD2_Pin,
                      GPIO_PIN_RESET);

    /*Configure GPIO pin Output Level */
    HAL_GPIO_WritePin(GPIOG,
                      GPIO_PIN_0 | GPIO_PIN_1 | GPIO_PIN_2 | GPIO_PIN_3 | USB_PowerSwitchOn_Pin,
                      GPIO_PIN_RESET);

    /*Configure GPIO pin Output Level */
    HAL_GPIO_WritePin(GPIOE, GPIO_PIN_12 | GPIO_PIN_13 | GPIO_PIN_14 | GPIO_PIN_15, GPIO_PIN_RESET);

    /*Configure GPIO pin Output Level */
    HAL_GPIO_WritePin(GPIOD,
                      LED_1_Pin | LED_2_Pin | LED_3_Pin | LED_4_Pin | LED_5_Pin | LED_6_Pin |
                          LED_7_Pin | LED_8_Pin,
                      GPIO_PIN_RESET);

    /*Configure GPIO pins : PE2 PE3 PE4 PE5
                             PE6 PE7 PE8 PE0 */
    GPIO_InitStruct.Pin = GPIO_PIN_2 | GPIO_PIN_3 | GPIO_PIN_4 | GPIO_PIN_5 | GPIO_PIN_6 |
                          GPIO_PIN_7 | GPIO_PIN_8 | GPIO_PIN_0;
    GPIO_InitStruct.Mode = GPIO_MODE_INPUT;
    GPIO_InitStruct.Pull = GPIO_NOPULL;
    HAL_GPIO_Init(GPIOE, &GPIO_InitStruct);

    /*Configure GPIO pin : USER_Btn_Pin */
    GPIO_InitStruct.Pin = USER_Btn_Pin;
    GPIO_InitStruct.Mode = GPIO_MODE_IT_RISING;
    GPIO_InitStruct.Pull = GPIO_NOPULL;
    HAL_GPIO_Init(USER_Btn_GPIO_Port, &GPIO_InitStruct);

    /*Configure GPIO pins : PF2 PF3 PF5 PF7
                             PF12 PF13 PF14 PF15 */
    GPIO_InitStruct.Pin = GPIO_PIN_2 | GPIO_PIN_3 | GPIO_PIN_5 | GPIO_PIN_7 | GPIO_PIN_12 |
                          GPIO_PIN_13 | GPIO_PIN_14 | GPIO_PIN_15;
    GPIO_InitStruct.Mode = GPIO_MODE_OUTPUT_PP;
    GPIO_InitStruct.Pull = GPIO_NOPULL;
    GPIO_InitStruct.Speed = GPIO_SPEED_FREQ_LOW;
    HAL_GPIO_Init(GPIOF, &GPIO_InitStruct);

    /*Configure GPIO pins : PF4 PF6 PF9 PF10
                             PF11 */
    GPIO_InitStruct.Pin = GPIO_PIN_4 | GPIO_PIN_6 | GPIO_PIN_9 | GPIO_PIN_10 | GPIO_PIN_11;
    GPIO_InitStruct.Mode = GPIO_MODE_ANALOG;
    GPIO_InitStruct.Pull = GPIO_NOPULL;
    HAL_GPIO_Init(GPIOF, &GPIO_InitStruct);

    /*Configure GPIO pin : PF8 */
    GPIO_InitStruct.Pin = GPIO_PIN_8;
    GPIO_InitStruct.Mode = GPIO_MODE_IT_RISING;
    GPIO_InitStruct.Pull = GPIO_NOPULL;
    HAL_GPIO_Init(GPIOF, &GPIO_InitStruct);

    /*Configure GPIO pins : PC0 PC1 PC3 PC4
                             PC5 */
    GPIO_InitStruct.Pin = GPIO_PIN_0 | GPIO_PIN_1 | GPIO_PIN_3 | GPIO_PIN_4 | GPIO_PIN_5;
    GPIO_InitStruct.Mode = GPIO_MODE_ANALOG;
    GPIO_InitStruct.Pull = GPIO_NOPULL;
    HAL_GPIO_Init(GPIOC, &GPIO_InitStruct);

    /*Configure GPIO pins : PA1 PA2 PA4 PA5
                             PA15 */
    GPIO_InitStruct.Pin = GPIO_PIN_1 | GPIO_PIN_2 | GPIO_PIN_4 | GPIO_PIN_5 | GPIO_PIN_15;
    GPIO_InitStruct.Mode = GPIO_MODE_ANALOG;
    GPIO_InitStruct.Pull = GPIO_NOPULL;
    HAL_GPIO_Init(GPIOA, &GPIO_InitStruct);

    /*Configure GPIO pins : PB0 PB1 PB2 PB13
                             LD3_Pin LD2_Pin */
    GPIO_InitStruct.Pin = GPIO_PIN_0 | GPIO_PIN_1 | GPIO_PIN_2 | GPIO_PIN_13 | LD3_Pin | LD2_Pin;
    GPIO_InitStruct.Mode = GPIO_MODE_OUTPUT_PP;
    GPIO_InitStruct.Pull = GPIO_NOPULL;
    GPIO_InitStruct.Speed = GPIO_SPEED_FREQ_LOW;
    HAL_GPIO_Init(GPIOB, &GPIO_InitStruct);

    /*Configure GPIO pins : PG0 PG1 PG2 PG3
                             USB_PowerSwitchOn_Pin */
    GPIO_InitStruct.Pin = GPIO_PIN_0 | GPIO_PIN_1 | GPIO_PIN_2 | GPIO_PIN_3 | USB_PowerSwitchOn_Pin;
    GPIO_InitStruct.Mode = GPIO_MODE_OUTPUT_PP;
    GPIO_InitStruct.Pull = GPIO_NOPULL;
    GPIO_InitStruct.Speed = GPIO_SPEED_FREQ_LOW;
    HAL_GPIO_Init(GPIOG, &GPIO_InitStruct);

    /*Configure GPIO pin : PE10 */
    GPIO_InitStruct.Pin = GPIO_PIN_10;
    GPIO_InitStruct.Mode = GPIO_MODE_IT_RISING;
    GPIO_InitStruct.Pull = GPIO_NOPULL;
    HAL_GPIO_Init(GPIOE, &GPIO_InitStruct);

    /*Configure GPIO pins : PE12 PE13 PE14 PE15 */
    GPIO_InitStruct.Pin = GPIO_PIN_12 | GPIO_PIN_13 | GPIO_PIN_14 | GPIO_PIN_15;
    GPIO_InitStruct.Mode = GPIO_MODE_OUTPUT_PP;
    GPIO_InitStruct.Pull = GPIO_NOPULL;
    GPIO_InitStruct.Speed = GPIO_SPEED_FREQ_LOW;
    HAL_GPIO_Init(GPIOE, &GPIO_InitStruct);

    /*Configure GPIO pins : PB11 PB4 PB5 PB8 */
    GPIO_InitStruct.Pin = GPIO_PIN_11 | GPIO_PIN_4 | GPIO_PIN_5 | GPIO_PIN_8;
    GPIO_InitStruct.Mode = GPIO_MODE_ANALOG;
    GPIO_InitStruct.Pull = GPIO_NOPULL;
    HAL_GPIO_Init(GPIOB, &GPIO_InitStruct);

    /*Configure GPIO pin : PB12 */
    GPIO_InitStruct.Pin = GPIO_PIN_12;
    GPIO_InitStruct.Mode = GPIO_MODE_IT_RISING;
    GPIO_InitStruct.Pull = GPIO_NOPULL;
    HAL_GPIO_Init(GPIOB, &GPIO_InitStruct);

    /*Configure GPIO pins : PD10 PD11 PD14 PD15 */
    GPIO_InitStruct.Pin = GPIO_PIN_10 | GPIO_PIN_11 | GPIO_PIN_14 | GPIO_PIN_15;
    GPIO_InitStruct.Mode = GPIO_MODE_ANALOG;
    GPIO_InitStruct.Pull = GPIO_NOPULL;
    HAL_GPIO_Init(GPIOD, &GPIO_InitStruct);

    /*Configure GPIO pins : PG4 PG5 PG8 PG9
                             PG10 PG11 PG12 PG13
                             PG14 PG15 */
    GPIO_InitStruct.Pin = GPIO_PIN_4 | GPIO_PIN_5 | GPIO_PIN_8 | GPIO_PIN_9 | GPIO_PIN_10 |
                          GPIO_PIN_11 | GPIO_PIN_12 | GPIO_PIN_13 | GPIO_PIN_14 | GPIO_PIN_15;
    GPIO_InitStruct.Mode = GPIO_MODE_ANALOG;
    GPIO_InitStruct.Pull = GPIO_NOPULL;
    HAL_GPIO_Init(GPIOG, &GPIO_InitStruct);

    /*Configure GPIO pin : USB_OverCurrent_Pin */
    GPIO_InitStruct.Pin = USB_OverCurrent_Pin;
    GPIO_InitStruct.Mode = GPIO_MODE_INPUT;
    GPIO_InitStruct.Pull = GPIO_NOPULL;
    HAL_GPIO_Init(USB_OverCurrent_GPIO_Port, &GPIO_InitStruct);

    /*Configure GPIO pins : USB_SOF_Pin USB_ID_Pin USB_DM_Pin USB_DP_Pin */
    GPIO_InitStruct.Pin = USB_SOF_Pin | USB_ID_Pin | USB_DM_Pin | USB_DP_Pin;
    GPIO_InitStruct.Mode = GPIO_MODE_AF_PP;
    GPIO_InitStruct.Pull = GPIO_NOPULL;
    GPIO_InitStruct.Speed = GPIO_SPEED_FREQ_VERY_HIGH;
    GPIO_InitStruct.Alternate = GPIO_AF10_OTG_FS;
    HAL_GPIO_Init(GPIOA, &GPIO_InitStruct);

    /*Configure GPIO pin : USB_VBUS_Pin */
    GPIO_InitStruct.Pin = USB_VBUS_Pin;
    GPIO_InitStruct.Mode = GPIO_MODE_INPUT;
    GPIO_InitStruct.Pull = GPIO_NOPULL;
    HAL_GPIO_Init(USB_VBUS_GPIO_Port, &GPIO_InitStruct);

    /*Configure GPIO pins : LED_1_Pin LED_2_Pin LED_3_Pin LED_4_Pin
                             LED_5_Pin LED_6_Pin LED_7_Pin LED_8_Pin */
    GPIO_InitStruct.Pin = LED_1_Pin | LED_2_Pin | LED_3_Pin | LED_4_Pin | LED_5_Pin | LED_6_Pin |
                          LED_7_Pin | LED_8_Pin;
    GPIO_InitStruct.Mode = GPIO_MODE_OUTPUT_PP;
    GPIO_InitStruct.Pull = GPIO_NOPULL;
    GPIO_InitStruct.Speed = GPIO_SPEED_FREQ_LOW;
    HAL_GPIO_Init(GPIOD, &GPIO_InitStruct);

    /*Configure GPIO pin : PE1 */
    GPIO_InitStruct.Pin = GPIO_PIN_1;
    GPIO_InitStruct.Mode = GPIO_MODE_ANALOG;
    GPIO_InitStruct.Pull = GPIO_NOPULL;
    HAL_GPIO_Init(GPIOE, &GPIO_InitStruct);

    /* EXTI interrupt init*/
    HAL_NVIC_SetPriority(EXTI9_5_IRQn, 0, 0);
    HAL_NVIC_EnableIRQ(EXTI9_5_IRQn);

    HAL_NVIC_SetPriority(EXTI15_10_IRQn, 0, 0);
    HAL_NVIC_EnableIRQ(EXTI15_10_IRQn);

}

void Error_Handler(void) {
    __disable_irq();
    while (1) {
    }
}
#ifdef USE_FULL_ASSERT
/**
 * @brief  Reports the name of the source file and the source line number
 *         where the assert_param error has occurred.
 * @param  file: pointer to the source file name
 * @param  line: assert_param error line source number
 * @retval None
 */
void assert_failed(uint8_t* file, uint32_t line) {
    /* USER CODE BEGIN 6 */
    /* User can add his own implementation to report the file name and line
       number, ex: printf("Wrong parameters value: file %s on line %d\r\n", file,
       line) */
    /* USER CODE END 6 */
}
#endif /* USE_FULL_ASSERT */
